# MKS22F12 register map
Vendor: Freescale Semiconductor, Inc.; Series: Kinetis_K; File version: 1.6
CPU: CM4 r0p1, little endian, no MPU, FPU, VTOR, 4 interrupt priority bits
Registers are 32-bit, read-write, reset 0x0 unless marked. A register's access mark holds for its fields unless they carry their own. Offsets are from the block's base; [hi:lo] are bit positions; {n}, {i} and the like mark numbered series; 'fields as' and 'values as' point back to an identical list.

## LLWU — Low leakage wakeup unit
Base 0x4007C000; register names take the prefix LLWU_
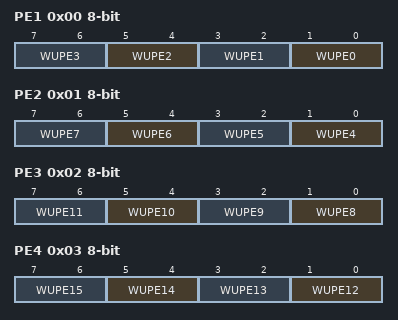
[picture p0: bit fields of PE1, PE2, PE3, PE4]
0x00 PE1 8-bit — LLWU Pin Enable 1 register
  [all] fields
    0=External input pin disabled as wakeup input; 1=External input pin enabled with rising edge detection; 2=External input pin enabled with falling edge detection; 3=External input pin enabled with any change detection
  [2n+1:2n] WUPE{n} (n=0..3) — Wakeup Pin Enable For LLWU_P{n}
0x01 PE2 8-bit — LLWU Pin Enable 2 register
  [all] fields
    values as the fields of PE1
  [2n-7:2n-8] WUPE{n} (n=4..7) — Wakeup Pin Enable For LLWU_P{n}
0x02 PE3 8-bit — LLWU Pin Enable 3 register
  [all] fields
    values as the fields of PE1
  [2n-15:2n-16] WUPE{n} (n=8..11) — Wakeup Pin Enable For LLWU_P{n}
0x03 PE4 8-bit — LLWU Pin Enable 4 register
  [all] fields
    values as the fields of PE1
  [2n-23:2n-24] WUPE{n} (n=12..15) — Wakeup Pin Enable For LLWU_P{n}
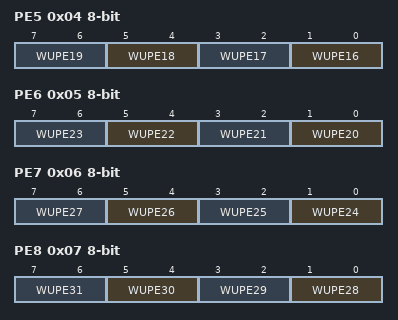
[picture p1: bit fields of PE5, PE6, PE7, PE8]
0x04 PE5 8-bit — LLWU Pin Enable 5 register
  [all] fields
    values as the fields of PE1
  [2n-31:2n-32] WUPE{n} (n=16..19) — Wakeup Pin Enable For LLWU_P{n}
0x05 PE6 8-bit — LLWU Pin Enable 6 register
  [all] fields
    values as the fields of PE1
  [2n-39:2n-40] WUPE{n} (n=20..23) — Wakeup Pin Enable For LLWU_P{n}
0x06 PE7 8-bit — LLWU Pin Enable 7 register
  [all] fields
    values as the fields of PE1
  [2n-47:2n-48] WUPE{n} (n=24..27) — Wakeup Pin Enable For LLWU_P{n}
0x07 PE8 8-bit — LLWU Pin Enable 8 register
  [all] fields
    values as the fields of PE1
  [2n-55:2n-56] WUPE{n} (n=28..31) — Wakeup Pin Enable For LLWU_P{n}
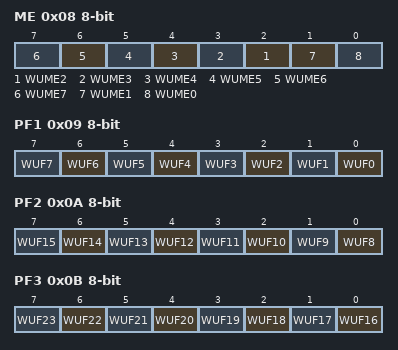
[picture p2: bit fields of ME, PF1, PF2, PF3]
0x08 ME 8-bit — LLWU Module Enable register
  [all] fields
    0=Internal module flag not used as wakeup source; 1=Internal module flag used as wakeup source
  [n] WUME{n} (n=2..7) — Wakeup Module Enable For Module {n}
  [1] WUME1 — Wakeup Module Enable for Module 1
  [0] WUME0 — Wakeup Module Enable For Module 0
0x09 PF1 8-bit — LLWU Pin Flag 1 register
  [n] WUF{n} (n=0..7) — Wakeup Flag For LLWU_P{n}
    0=LLWU_P{n} input was not a wakeup source; 1=LLWU_P{n} input was a wakeup source
0x0A PF2 8-bit — LLWU Pin Flag 2 register
  [n-8] WUF{n} (n=8..15) — Wakeup Flag For LLWU_P{n}
    values as PF1.WUF0
0x0B PF3 8-bit — LLWU Pin Flag 3 register
  [n-16] WUF{n} (n=16..23) — Wakeup Flag For LLWU_P{n}
    values as PF1.WUF0
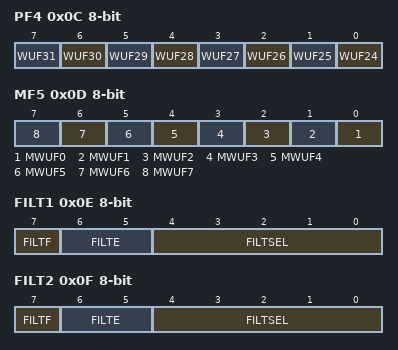
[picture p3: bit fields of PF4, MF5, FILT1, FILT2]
0x0C PF4 8-bit — LLWU Pin Flag 4 register
  [n-24] WUF{n} (n=24..31) — Wakeup Flag For LLWU_P{n}
    values as PF1.WUF0
0x0D MF5 8-bit ro — LLWU Module Flag 5 register
  [n] MWUF{n} (n=0..7) — Wakeup flag For module {n}
    0=Module {n} input was not a wakeup source; 1=Module {n} input was a wakeup source
0x0E FILT1 8-bit — LLWU Pin Filter 1 register
  [7] FILTF — Filter Detect Flag
    0=Pin Filter 1 was not a wakeup source; 1=Pin Filter 1 was a wakeup source
  [6:5] FILTE — Digital Filter On External Pin
    0=Filter disabled; 1=Filter posedge detect enabled; 2=Filter negedge detect enabled; 3=Filter any edge detect enabled
  [4:0] FILTSEL — Filter Pin Select
    0=Select LLWU_P0 for filter; 31=Select LLWU_P31 for filter
0x0F FILT2 8-bit — LLWU Pin Filter 2 register
  [7] FILTF — Filter Detect Flag
    0=Pin Filter 2 was not a wakeup source; 1=Pin Filter 2 was a wakeup source
  [6:5] FILTE — Digital Filter On External Pin
    values as FILT1.FILTE
  [4:0] FILTSEL — Filter Pin Select
    0=Select LLWU_P0 for filter; 31=Select LLWU_P31 for filter

## PMC — Power Management Controller
Base 0x4007D000; register names take the prefix PMC_
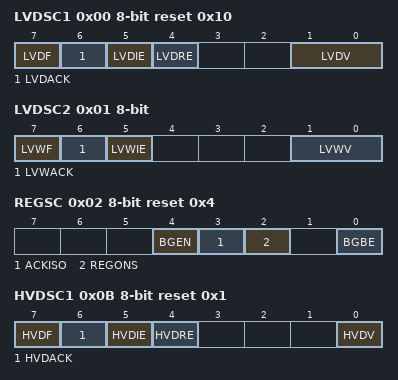
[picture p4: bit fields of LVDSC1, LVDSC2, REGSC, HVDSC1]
0x00 LVDSC1 8-bit reset 0x10 — Low Voltage Detect Status And Control 1 register
  [7] LVDF ro — Low-Voltage Detect Flag
    0=Low-voltage event not detected; 1=Low-voltage event detected
  [6] LVDACK wo — Low-Voltage Detect Acknowledge
  [5] LVDIE — Low-Voltage Detect Interrupt Enable
    0=Hardware interrupt disabled (use polling); 1=Request a hardware interrupt when LVDF = 1
  [4] LVDRE — Low-Voltage Detect Reset Enable
    0=LVDF does not generate hardware resets; 1=Force an MCU reset when LVDF = 1
  [1:0] LVDV — Low-Voltage Detect Voltage Select
    0=Low trip point selected (V LVD = V LVDL ); 1=High trip point selected (V LVD = V LVDH )
0x01 LVDSC2 8-bit — Low Voltage Detect Status And Control 2 register
  [7] LVWF ro — Low-Voltage Warning Flag
    0=Low-voltage warning event not detected; 1=Low-voltage warning event detected
  [6] LVWACK wo — Low-Voltage Warning Acknowledge
  [5] LVWIE — Low-Voltage Warning Interrupt Enable
    0=Hardware interrupt disabled (use polling); 1=Request a hardware interrupt when LVWF = 1
  [1:0] LVWV — Low-Voltage Warning Voltage Select
    0=Low trip point selected (VLVW = VLVW1); 1=Mid 1 trip point selected (VLVW = VLVW2); 2=Mid 2 trip point selected (VLVW = VLVW3); 3=High trip point selected (VLVW = VLVW4)
0x02 REGSC 8-bit reset 0x4 — Regulator Status And Control register
  [4] BGEN — Bandgap Enable In VLPx Operation
    0=Bandgap voltage reference is disabled in VLPx , LLS , and VLLSx modes; 1=Bandgap voltage reference is enabled in VLPx , LLS , and VLLSx modes
  [3] ACKISO — Acknowledge Isolation
    0=Peripherals and I/O pads are in normal run state; 1=Certain peripherals and I/O pads are in an isolated and latched state
  [2] REGONS ro — Regulator In Run Regulation Status
    0=Regulator is in stop regulation or in transition to/from it; 1=Regulator is in run regulation
  [0] BGBE — Bandgap Buffer Enable
    0=Bandgap buffer not enabled; 1=Bandgap buffer enabled
0x0B HVDSC1 8-bit reset 0x1 — High Voltage Detect Status And Control 1 register
  [7] HVDF ro — High-Voltage Detect Flag
    0=High-voltage event not detected; 1=High-voltage event detected
  [6] HVDACK wo — High-Voltage Detect Acknowledge
  [5] HVDIE — High-Voltage Detect Interrupt Enable
    0=Hardware interrupt disabled (use polling); 1=Request a hardware interrupt when HVDF = 1
  [4] HVDRE — High-Voltage Detect Reset Enable
    0=HVDF does not generate hardware resets; 1=Force an MCU reset when HVDF = 1
  [0] HVDV — High-Voltage Detect Voltage Select
    0=Low trip point selected (V HVD = V HVDL ); 1=High trip point selected (V HVD = V HVDH )
